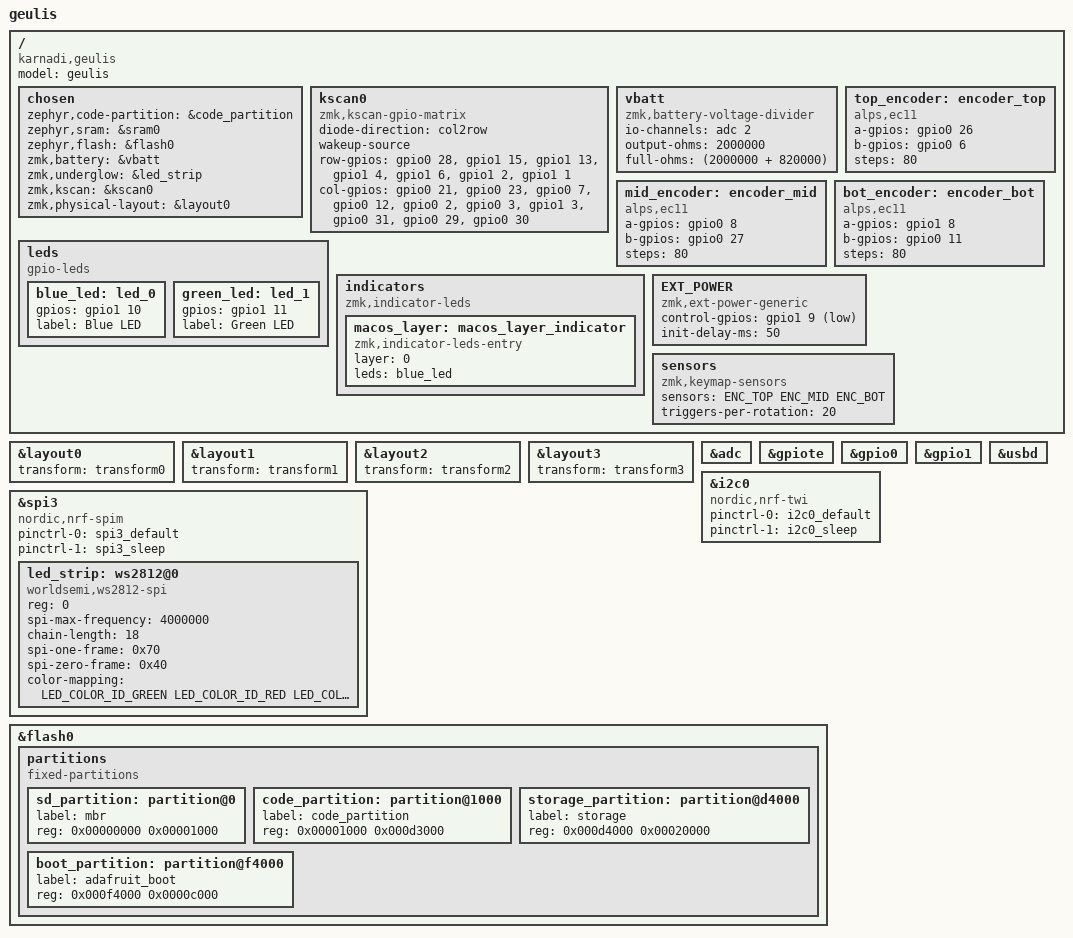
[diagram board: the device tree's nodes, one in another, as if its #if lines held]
/*
 * Copyright (c) 2024 Ujang Karnadi
 *
 * SPDX-License-Identifier: MIT
 */


 /dts-v1/;
#include <nordic/nrf52840_qiaa.dtsi>

#include <dt-bindings/led/led.h>

#include "geulis_options.h"
#include "geulis-pinctrl.dtsi"
#include "geulis-layout.dtsi"
#include "geulis-transform.dtsi"

// Split backspace and split right shift
&layout0 {
    transform = <&transform0>;
};

// Split backspace and one right shift
&layout1 {
    transform = <&transform1>;
};

// One backspace and split right shift
&layout2 {
    transform = <&transform2>;
};

&layout3 {
    transform = <&transform3>;
};



/ {
    model = "geulis";
    compatible = "karnadi,geulis";

    chosen {
        zephyr,code-partition = &code_partition;
        zephyr,sram = &sram0;
        zephyr,flash = &flash0;
        zmk,battery = &vbatt;
#if GEULIS_RGB_UNDERGLOW_ON
        zmk,underglow = &led_strip;
#endif
        zmk,kscan = &kscan0;
        zmk,physical-layout = &layout0;
    };

    kscan0: kscan0 {
        compatible = "zmk,kscan-gpio-matrix";
        diode-direction = "col2row";
        wakeup-source;
        
        row-gpios
            = <&gpio0 28 (GPIO_ACTIVE_HIGH | GPIO_PULL_DOWN)>
            , <&gpio1 15 (GPIO_ACTIVE_HIGH | GPIO_PULL_DOWN)>
            , <&gpio1 13 (GPIO_ACTIVE_HIGH | GPIO_PULL_DOWN)>
            , <&gpio1 4  (GPIO_ACTIVE_HIGH | GPIO_PULL_DOWN)>
            , <&gpio1 6  (GPIO_ACTIVE_HIGH | GPIO_PULL_DOWN)>
            , <&gpio1 2  (GPIO_ACTIVE_HIGH | GPIO_PULL_DOWN)>
            , <&gpio1 1  (GPIO_ACTIVE_HIGH | GPIO_PULL_DOWN)>
            ;

        col-gpios
            = <&gpio0 21 GPIO_ACTIVE_HIGH >
            , <&gpio0 23 GPIO_ACTIVE_HIGH >
            , <&gpio0 7 GPIO_ACTIVE_HIGH >
            , <&gpio0 12 GPIO_ACTIVE_HIGH >
            , <&gpio0 2 GPIO_ACTIVE_HIGH >
            , <&gpio0 3 GPIO_ACTIVE_HIGH >
            , <&gpio1 3 GPIO_ACTIVE_HIGH >
            , <&gpio0 31 GPIO_ACTIVE_HIGH >
            , <&gpio0 29 GPIO_ACTIVE_HIGH >
            , <&gpio0 30 GPIO_ACTIVE_HIGH >
            ;
    };

    vbatt: vbatt {
        compatible = "zmk,battery-voltage-divider";
        io-channels = <&adc 2>;
        output-ohms = <2000000>;
        full-ohms = <(2000000 + 820000)>;
    };

    top_encoder: encoder_top {
        compatible = "alps,ec11";
        a-gpios = <&gpio0 26 (GPIO_ACTIVE_HIGH | GPIO_PULL_UP)>;
        b-gpios = <&gpio0 6 (GPIO_ACTIVE_HIGH | GPIO_PULL_UP)>;
        steps = <80>;
#if GEULIS_ENCODER_TOP_ON
        status = "okay";
#else
        status = "disabled";
#endif
    };

    mid_encoder: encoder_mid {
        compatible = "alps,ec11";
        a-gpios = <&gpio0 8 (GPIO_ACTIVE_HIGH | GPIO_PULL_UP)>;
        b-gpios = <&gpio0 27 (GPIO_ACTIVE_HIGH | GPIO_PULL_UP)>;
        steps = <80>;
#if GEULIS_ENCODER_MID_ON
        status = "okay";
#else
        status = "disabled";
#endif
    };

    bot_encoder: encoder_bot {
        compatible = "alps,ec11";
        a-gpios = <&gpio1 8 (GPIO_ACTIVE_HIGH | GPIO_PULL_UP)>;
        b-gpios = <&gpio0 11 (GPIO_ACTIVE_HIGH | GPIO_PULL_UP)>;
        steps = <80>;
#if GEULIS_ENCODER_BOT_ON
        status = "okay";
#else
        status = "disabled";
#endif
    };

    leds {
		compatible = "gpio-leds";

		blue_led: led_0 {
			gpios = <&gpio1 10 GPIO_ACTIVE_HIGH>;
			label = "Blue LED";
		};

        green_led: led_1 {
            gpios = <&gpio1 11 GPIO_ACTIVE_HIGH>;
            label = "Green LED";
        };
    };

    indicators {
        compatible = "zmk,indicator-leds";

        // macOS layer (index 0) active -> blue LED (P1.10).
        macos_layer: macos_layer_indicator {
            compatible = "zmk,indicator-leds-entry";
            layer = <0>;
            leds = <&blue_led>;
        };
    };

    // Node name must match original "EXT_POWER" label to preserve user settings.
    EXT_POWER {
        compatible = "zmk,ext-power-generic";
        control-gpios = <&gpio1 9 GPIO_ACTIVE_LOW>;
        init-delay-ms = <50>;
    };

    sensors {
        compatible = "zmk,keymap-sensors";
/*
 * Build the `sensors` phandle list from the enabled encoders. Each
 * ENC_* macro expands to either `&foo_encoder` (when enabled) or
 * nothing — the wrapping `<>` are part of the assignment itself.
 */
#if GEULIS_ENCODER_TOP_ON
#define ENC_TOP &top_encoder
#else
#define ENC_TOP
#endif
#if GEULIS_ENCODER_MID_ON
#define ENC_MID &mid_encoder
#else
#define ENC_MID
#endif
#if GEULIS_ENCODER_BOT_ON
#define ENC_BOT &bot_encoder
#else
#define ENC_BOT
#endif
#if !(GEULIS_ENCODER_TOP_ON || GEULIS_ENCODER_MID_ON || GEULIS_ENCODER_BOT_ON)
#error "At least one of GEULIS_ENCODER_TOP/MID/BOT_ON must be 1"
#endif
        sensors = < ENC_TOP ENC_MID ENC_BOT >;
#undef ENC_TOP
#undef ENC_MID
#undef ENC_BOT
        triggers-per-rotation = <20>;
    };

};

&adc {
    status = "okay";
};

&gpiote {
    status = "okay";
};

&gpio0 {
    status = "okay";
};

&gpio1 {
    status = "okay";
};


&i2c0 {
    compatible = "nordic,nrf-twi";
    pinctrl-0 = <&i2c0_default>;
    pinctrl-1 = <&i2c0_sleep>;
    pinctrl-names = "default", "sleep";
};

&spi3 {
    compatible = "nordic,nrf-spim";
    pinctrl-0 = <&spi3_default>;
    pinctrl-1 = <&spi3_sleep>;
    pinctrl-names = "default", "sleep";
#if GEULIS_RGB_UNDERGLOW_ON
    status = "okay";

    led_strip: ws2812@0{
        compatible = "worldsemi,ws2812-spi";

        /* SPI */
        reg = <0>; /* ignored, but necessary for SPI bindings */
        spi-max-frequency = <4000000>;

        /* WS2812 */
        chain-length = <18>; /* LED strip length */
        spi-one-frame = <0x70>;
        spi-zero-frame = <0x40>;
        color-mapping = <LED_COLOR_ID_GREEN
                        LED_COLOR_ID_RED
                        LED_COLOR_ID_BLUE>;
    };
#endif
};

zephyr_udc0: &usbd {
    status = "okay";
};




&flash0 {
    /*
     * For more information, see:
     * http://docs.zephyrproject.org/latest/devices/dts/flash_partitions.html
     */
    partitions {
        compatible = "fixed-partitions";
		#address-cells = <1>;
		#size-cells = <1>;

		sd_partition: partition@0 {
			label = "mbr";
			reg = <0x00000000 0x00001000>;
		};

		code_partition: partition@1000 {
			label = "code_partition";
			reg = <0x00001000 0x000d3000>;
		};

		storage_partition: partition@d4000 {
			label = "storage";
			reg = <0x000d4000 0x00020000>;
		};

		boot_partition: partition@f4000 {
			label = "adafruit_boot";
			reg = <0x000f4000 0x0000c000>;
		};
    };
};
